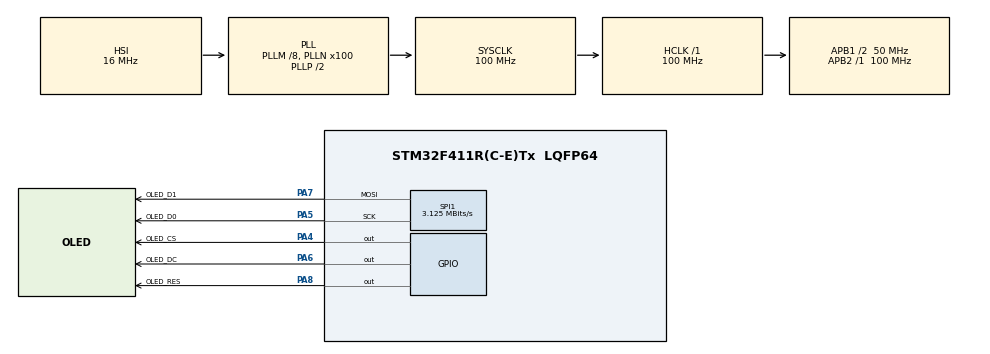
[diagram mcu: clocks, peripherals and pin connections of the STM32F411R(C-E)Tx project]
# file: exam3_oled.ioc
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Mcu.Family=STM32F4
Mcu.Name=STM32F411R(C-E)Tx
Mcu.Package=LQFP64
NVIC.PriorityGroup=NVIC_PRIORITYGROUP_4
PA4.GPIO_Label=OLED_CS
PA4.Signal=GPIO_Output
PA5.GPIO_Label=OLED_D0
PA5.Mode=TX_Only_Simplex_Unidirect_Master
PA5.Signal=SPI1_SCK
PA6.GPIO_Label=OLED_DC
PA6.Signal=GPIO_Output
PA7.GPIO_Label=OLED_D1
PA7.Mode=TX_Only_Simplex_Unidirect_Master
PA7.Signal=SPI1_MOSI
PA8.GPIO_Label=OLED_RES
PA8.Signal=GPIO_Output
ProjectManager.HeapSize=0x200
ProjectManager.StackSize=0x400
ProjectManager.TargetToolchain=STM32CubeIDE
RCC.48MHZClocksFreq_Value=50000000
RCC.AHBFreq_Value=100000000
RCC.APB1CLKDivider=RCC_HCLK_DIV2
RCC.APB1Freq_Value=50000000
RCC.APB1TimFreq_Value=100000000
RCC.APB2Freq_Value=100000000
RCC.APB2TimFreq_Value=100000000
RCC.CortexFreq_Value=100000000
RCC.HCLKFreq_Value=100000000
RCC.HSE_VALUE=25000000
RCC.HSI_VALUE=16000000
RCC.LSE_VALUE=32768
RCC.PLLM=8
RCC.PLLN=100
RCC.SYSCLKFreq_VALUE=100000000
RCC.SYSCLKSource=RCC_SYSCLKSOURCE_PLLCLK
RCC.VCOOutputFreq_Value=200000000
SPI1.BaudRatePrescaler=SPI_BAUDRATEPRESCALER_32
SPI1.CLKPhase=SPI_PHASE_2EDGE
SPI1.CLKPolarity=SPI_POLARITY_HIGH
SPI1.CalculateBaudRate=3.125 MBits/s
SPI1.Direction=SPI_DIRECTION_2LINES
SPI1.Mode=SPI_MODE_MASTER
SPI1.VirtualNSS=VM_NSSHARD
SPI1.VirtualType=VM_MASTER
board=custom

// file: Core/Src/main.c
/* USER CODE BEGIN Header */
/**
  ******************************************************************************
  * @file           : main.c
  * @brief          : Main program body
  ******************************************************************************
  * @attention
  *
  * Copyright (c) 2024 STMicroelectronics.
  * All rights reserved.
  *
  * This software is licensed under terms that can be found in the LICENSE file
  * in the root directory of this software component.
  * If no LICENSE file comes with this software, it is provided AS-IS.
  *
  ******************************************************************************
  */
/* USER CODE END Header */
#include "main.h"

/* USER CODE BEGIN Includes */
#include "u8g2/u8g2.h"
/* USER CODE END Includes */

SPI_HandleTypeDef hspi1;

void SystemClock_Config(void);
static void MX_GPIO_Init(void);
static void MX_SPI1_Init(void);
/* USER CODE BEGIN PFP */
uint8_t u8x8_stm32_gpio_and_delay(u8x8_t *u8x8, uint8_t msg, uint8_t arg_int, void *arg_ptr);
uint8_t u8x8_byte_stm32_hw_spi(u8x8_t *u8x8, uint8_t msg, uint8_t arg_int, void *arg_ptr);
/* USER CODE END PFP */

/* USER CODE BEGIN 0 */
static u8g2_t u8g2;
/* USER CODE END 0 */

int main(void)
{

  /* MCU Configuration--------------------------------------------------------*/

  /* Reset of all peripherals, Initializes the Flash interface and the Systick. */
  HAL_Init();

  /* Configure the system clock */
  SystemClock_Config();

  /* Initialize all configured peripherals */
  MX_GPIO_Init();
  MX_SPI1_Init();
  /* USER CODE BEGIN 2 */
  // ssd1306 setup
  u8g2_Setup_ssd1306_128x64_noname_f(&u8g2, U8G2_R0, u8x8_byte_stm32_hw_spi, u8x8_stm32_gpio_and_delay);
  u8g2_InitDisplay(&u8g2);				// init
  u8g2_SetPowerSave(&u8g2, 0);		// 1 is power off, 0 is on

  // Eng character
//  u8g2_ClearBuffer(&u8g2);
//  u8g2_SetDrawColor(&u8g2, 1);
//  u8g2_SetFont(&u8g2, u8g2_font_5x7_mf);
//  u8g2_DrawStr(&u8g2, 2, 10, "Hello world!");
//  // u8g2_DrawLine(&u8g2, 0, 0, 127, 63);
//  u8g2_SendBuffer(&u8g2);

  // Kor character
  u8g2_ClearBuffer(&u8g2);
  u8g2_SetDrawColor(&u8g2, 1);
  // u8g2_font_unifont_t_korean1 has not much letter
  // u8g2_font_unifont_t_korean2 has most letter
  u8g2_SetFont(&u8g2, u8g2_font_unifont_t_korean2);
  u8g2_DrawUTF8(&u8g2, 2, 30, "안녕 world!");
  u8g2_SendBuffer(&u8g2);

  /* USER CODE END 2 */

  /* Infinite loop */
  while (1)
  {

  }
}

void SystemClock_Config(void)
{
  RCC_OscInitTypeDef RCC_OscInitStruct = {0};
  RCC_ClkInitTypeDef RCC_ClkInitStruct = {0};

  /** Configure the main internal regulator output voltage
  */
  __HAL_RCC_PWR_CLK_ENABLE();
  __HAL_PWR_VOLTAGESCALING_CONFIG(PWR_REGULATOR_VOLTAGE_SCALE1);

  /** Initializes the RCC Oscillators according to the specified parameters
  * in the RCC_OscInitTypeDef structure.
  */
  RCC_OscInitStruct.OscillatorType = RCC_OSCILLATORTYPE_HSI;
  RCC_OscInitStruct.HSIState = RCC_HSI_ON;
  RCC_OscInitStruct.HSICalibrationValue = RCC_HSICALIBRATION_DEFAULT;
  RCC_OscInitStruct.PLL.PLLState = RCC_PLL_ON;
  RCC_OscInitStruct.PLL.PLLSource = RCC_PLLSOURCE_HSI;
  RCC_OscInitStruct.PLL.PLLM = 8;
  RCC_OscInitStruct.PLL.PLLN = 100;
  RCC_OscInitStruct.PLL.PLLP = RCC_PLLP_DIV2;
  RCC_OscInitStruct.PLL.PLLQ = 4;
  if (HAL_RCC_OscConfig(&RCC_OscInitStruct) != HAL_OK)
  {
    Error_Handler();
  }

  /** Initializes the CPU, AHB and APB buses clocks
  */
  RCC_ClkInitStruct.ClockType = RCC_CLOCKTYPE_HCLK|RCC_CLOCKTYPE_SYSCLK
                              |RCC_CLOCKTYPE_PCLK1|RCC_CLOCKTYPE_PCLK2;
  RCC_ClkInitStruct.SYSCLKSource = RCC_SYSCLKSOURCE_PLLCLK;
  RCC_ClkInitStruct.AHBCLKDivider = RCC_SYSCLK_DIV1;
  RCC_ClkInitStruct.APB1CLKDivider = RCC_HCLK_DIV2;
  RCC_ClkInitStruct.APB2CLKDivider = RCC_HCLK_DIV1;

  if (HAL_RCC_ClockConfig(&RCC_ClkInitStruct, FLASH_LATENCY_3) != HAL_OK)
  {
    Error_Handler();
  }
}

static void MX_SPI1_Init(void)
{

  /* SPI1 parameter configuration*/
  hspi1.Instance = SPI1;
  hspi1.Init.Mode = SPI_MODE_MASTER;
  hspi1.Init.Direction = SPI_DIRECTION_2LINES;
  hspi1.Init.DataSize = SPI_DATASIZE_8BIT;
  hspi1.Init.CLKPolarity = SPI_POLARITY_HIGH;
  hspi1.Init.CLKPhase = SPI_PHASE_2EDGE;
  hspi1.Init.NSS = SPI_NSS_SOFT;
  hspi1.Init.BaudRatePrescaler = SPI_BAUDRATEPRESCALER_32;
  hspi1.Init.FirstBit = SPI_FIRSTBIT_MSB;
  hspi1.Init.TIMode = SPI_TIMODE_DISABLE;
  hspi1.Init.CRCCalculation = SPI_CRCCALCULATION_DISABLE;
  hspi1.Init.CRCPolynomial = 10;
  if (HAL_SPI_Init(&hspi1) != HAL_OK)
  {
    Error_Handler();
  }

}

static void MX_GPIO_Init(void)
{
  GPIO_InitTypeDef GPIO_InitStruct = {0};

  /* GPIO Ports Clock Enable */
  __HAL_RCC_GPIOA_CLK_ENABLE();

  /*Configure GPIO pin Output Level */
  HAL_GPIO_WritePin(GPIOA, OLED_CS_Pin|OLED_DC_Pin|OLED_RES_Pin, GPIO_PIN_RESET);

  /*Configure GPIO pins : OLED_CS_Pin OLED_DC_Pin OLED_RES_Pin */
  GPIO_InitStruct.Pin = OLED_CS_Pin|OLED_DC_Pin|OLED_RES_Pin;
  GPIO_InitStruct.Mode = GPIO_MODE_OUTPUT_PP;
  GPIO_InitStruct.Pull = GPIO_NOPULL;
  GPIO_InitStruct.Speed = GPIO_SPEED_FREQ_LOW;
  HAL_GPIO_Init(GPIOA, &GPIO_InitStruct);

}

void Error_Handler(void)
{
  __disable_irq();
  while (1)
  {
  }
}
